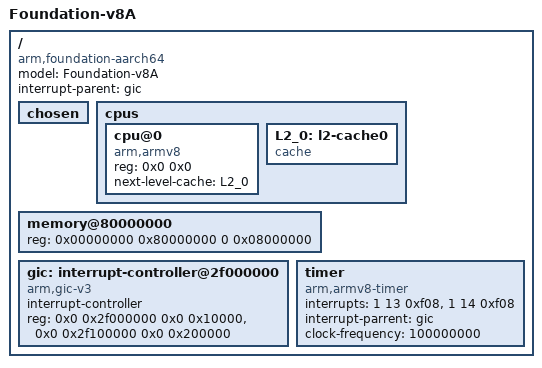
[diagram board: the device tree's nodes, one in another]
/*
 * ARM Ltd.
 *
 * ARMv8 Foundation model DTS (GICv3 configuration)
 */
/dts-v1/;

/ {
	model = "Foundation-v8A";
	compatible = "arm,foundation-aarch64", "arm,vexpress";
	interrupt-parent = <&gic>;
	#address-cells = <2>;
	#size-cells = <2>;

	chosen { };

	cpus {
		#address-cells = <2>;
		#size-cells = <0>;

		cpu@0 {
			device_type = "cpu";
			compatible = "arm,armv8";
			reg = <0x0 0x0>;
			next-level-cache = <&L2_0>;
		};

		L2_0: l2-cache0 {
			compatible = "cache";
		};
	};

	/* 128 MB of memory from address 0x80000000 to 0x88000000 (64bit) */
	memory@80000000 {
		device_type = "memory";
		reg = <0x00000000 0x80000000 0  0x08000000>;
	};

	gic: interrupt-controller@2f000000 {
		compatible = "arm,gic-v3";
		#interrupt-cells = <3>;
		#size-cells = <2>;
		interrupt-controller;
		reg =	<0x0 0x2f000000 0x0 0x10000>,	/* Distributor */
			<0x0 0x2f100000 0x0 0x200000>;	/* Redistributor */
	};

	/*
	 * Don't advertise virtual timer interrupts in the guest because on
	 * ARMv8.0 there's only support for trapping access to the physical
	 * timer registers.
	 */
	timer {
		compatible = "arm,armv8-timer";
		interrupts = <1 13 0xf08>,
			     <1 14 0xf08>;
		interrupt-parrent = <&gic>;
		clock-frequency = <100000000>;
	};
};
